# GD32H77x_78x register map
File version: 1.0
CPU: CM7 r1p2, little endian, MPU, FPU, 4 interrupt priority bits
Registers are 32-bit, read-write, reset 0x0 unless marked. A register's access mark holds for its fields unless they carry their own. Offsets are from the block's base; [hi:lo] are bit positions; {n}, {i} and the like mark numbered series.

## GPSI — General parallel slaver interfac
Base 0x48020200
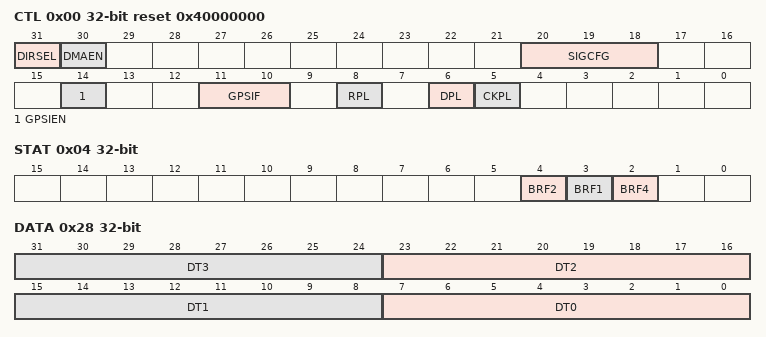
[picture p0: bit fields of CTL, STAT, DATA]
0x00 CTL reset 0x40000000 — Control register
  [31] DIRSEL — Data direction.
  [30] DMAEN — DMA enable bit
  [20:18] SIGCFG — Data enable and ready setting bits.
  [14] GPSIEN — GPSI enable bit.
  [11:10] GPSIF — Captured data width select.
  [8] RPL — GPSI_RDY polarity.
  [6] DPL — GPSI_DE polarity.
  [5] CKPL — Parallel data clock polarity.
0x04 STAT ro — Status register
  [4] BRF2 — FIFO is ready to transfer two bytes.
  [3] BRF1 — FIFO is ready to transfer one byte.
  [2] BRF4 — FIFO is ready to transfer four bytes.
0x08 INTF ro — Interrupt status register
  [1] OUIF — Data buffer overrun or underrun interrupt status.
0x0C INTEN — Interrupt enable register
  [1] OUIE — Data buffer overrun or underrun interrupt enable.
0x10 MINTF ro — Masked interrupt status register
  [1] OUMIF — Data buffer overrun or underrun masked interrupt status.
0x14 INTC wo — Interrupt clear register
  [1] OUFC — Clear data buffer overrun or underrun interrupt status.
0x28 DATA
  [8n+7:8n] DT{n} (n=0..3) — GPSI DATA {n}.

## HAU — HAU acceleration unit
Base 0x48021400
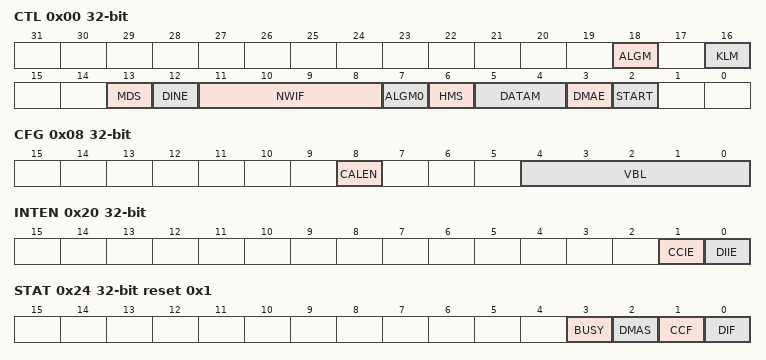
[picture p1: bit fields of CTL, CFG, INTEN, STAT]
0x00 CTL access per field — HAU control register
  [18] ALGM rw — Algorithm selection bit 1
  [16] KLM rw — Key length mode
  [13] MDS rw — Multiple DMA selection
  [12] DINE ro — DI register is not empty
  [11:8] NWIF ro — Number of words in IN FIFO
  [7] ALGM0 rw — Algorithm selection bit 0
  [6] HMS rw — HAU mode selection
  [5:4] DATAM rw — Data type mode
  [3] DMAE rw — DMA enable
  [2] START wo — Start message digest calculation
0x04 DI — HAU data input register
  [31:0] DI — Message data input
0x08 CFG access per field — HAU configuration register
  [8] CALEN wo — Digest calculation enable
  [4:0] VBL rw — Valid bits length in the last word
{0xC+4i} DO{i} ro (i=0..4) — HAU data output register
  [31:0] DO{i} — message digest result of hash algorithm
0x20 INTEN — HAU interrupt enable register
  [1] CCIE — calculation completion interrupt enable
  [0] DIIE — Data input interrupt enable
0x24 STAT ro reset 0x1 — HAU status and interrupt flag register
  [3] BUSY — Busy flag bit
  [2] DMAS — DMA status flag
  [1] CCF — Digest calculation completion flag
  [0] DIF — Data input flag
0xF8 CTXS0 reset 0x2 — Context switch register x
  [31:0] CTX0 — The complete internal status
{0xF8+4i} CTXS{i} (i=1..53) — Context switch register x
  [31:0] CTX{i} — The complete internal status
{0x310+4i} DO{i} ro (i=5..7) — HAU data output register
  [31:0] DO{i} — message digest result of hash algorithm

## HDSL_general — HIPERFACE DSL encoder interface module
Base 0x4000DB80
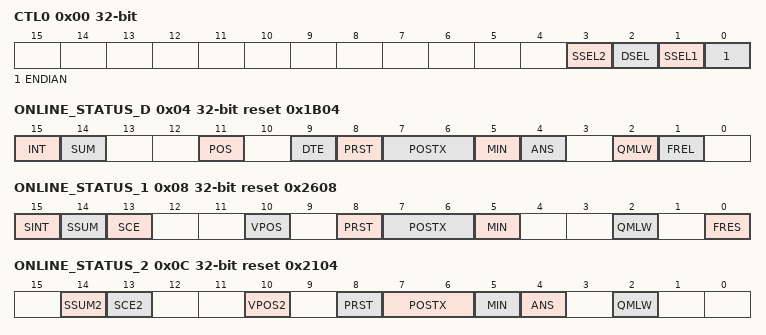
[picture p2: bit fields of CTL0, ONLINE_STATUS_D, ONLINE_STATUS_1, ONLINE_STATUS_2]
0x00 CTL0 — HDSL control register 0
  [3] SSEL2 — HIPERFACE DSL unit 0 safe channel 2 interface select
  [2] DSEL — HIPERFACE DSL unit 0 driver interface select
  [1] SSEL1 — HIPERFACE DSL unit 0 safe channel 1 interface select
  [0] ENDIAN — HIPERFACE DSL unit 0 endian Mode
0x04 ONLINE_STATUS_D ro reset 0x1B04 — HDSL online status (drive) register
  [15] INT — Status of the interrupt signal
  [14] SUM — Summary byte
  [11] POS — Estimator turned on
  [9] DTE — Deviation threshold error
  [8] PRST — Protocol reset
  [7:6] POSTX — Position transmission status
  [5] MIN — Acknowledgment of message Initialization
  [4] ANS — Incorrect answer detected
  [2] QMLW — Quality monitoring at low level
  [1] FREL — Channel status for long message
0x08 ONLINE_STATUS_1 ro reset 0x2608 — HDSL online status (safe channel 1) register
  [15] SINT — Status of the interrupt signal
  [14] SSUM — Safe summary bit
  [13] SCE — CRC Error on the Safe Channel
  [10] VPOS — Safe Position Invalid
  [8] PRST — Protocol reset
  [7:6] POSTX — Position transmission status
  [5] MIN — Acknowledgment of message Initialization
  [2] QMLW — Quality monitoring at low level
  [0] FRES — Channel Status for the short message
0x0C ONLINE_STATUS_2 ro reset 0x2104 — HDSL online status (safe channel 2) register
  [14] SSUM2 — Summary byte Channel 2
  [13] SCE2 — Transmission Error Channel 2
  [10] VPOS2 — Safe Position 2 Invalid
  [8] PRST — Protocol reset
  [7:6] POSTX — Position transmission status
  [5] MIN — Acknowledgment of message Initialization
  [4] ANS — Incorrect answer detected
  [2] QMLW — Quality monitoring at low level
0x10 SYNLK ro — HDSL sync lock register
  [0] SYNLK — Position sampling resolution locked
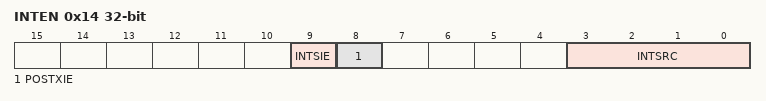
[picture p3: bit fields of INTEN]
0x14 INTEN — HDSL interrupt enable register
  [9] INTSIE — Interrupt_s enable
  [8] POSTXIE — POSTX interrupt enable
  [3:0] INTSRC — POSTX interrupt source
